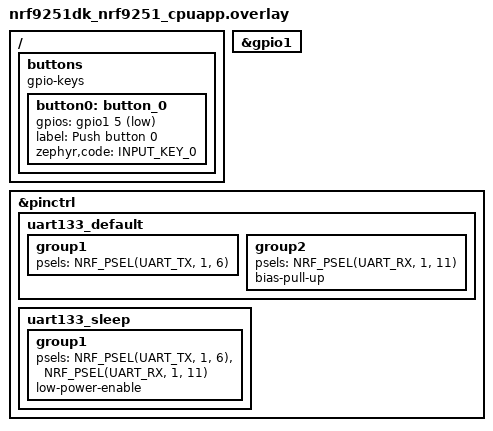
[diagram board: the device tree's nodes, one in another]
/*
 * Copyright (c) 2026 Nordic Semiconductor ASA
 *
 * SPDX-License-Identifier: LicenseRef-Nordic-5-Clause
 */

/ {
	/*
	 * Redefine sw0/button0 to use RXD0 - P1.05
	 * Thus, when sending character from host, there will be gpio interrupt,
	 * the same as originally triggered by sw0 button.
	 */
	buttons {
		compatible = "gpio-keys";

		button0: button_0 {
			gpios = <&gpio1 5 (GPIO_PULL_UP | GPIO_ACTIVE_LOW)>;
			label = "Push button 0";
			zephyr,code = <INPUT_KEY_0>;
		};
	};
};

&gpio1 {
	status = "okay";
};

&pinctrl {
	/*
	 * Redefine: RXD0 -> P1.11 (any other valid pin)
	 */
	uart133_default: uart133_default {
		group1 {
			psels = <NRF_PSEL(UART_TX, 1, 6)>;
		};

		group2 {
			psels = <NRF_PSEL(UART_RX, 1, 11)>;
			bias-pull-up;
		};
	};

	uart133_sleep: uart133_sleep {
		group1 {
			psels = <NRF_PSEL(UART_TX, 1, 6)>,
				<NRF_PSEL(UART_RX, 1, 11)>;
			low-power-enable;
		};
	};
};
